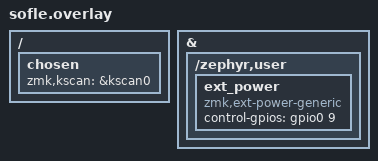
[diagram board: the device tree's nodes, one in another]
/ {
    chosen {
        zmk,kscan = &kscan0;
    };
};

&{/zephyr,user {
    ext_power {
        compatible = "zmk,ext-power-generic";
        control-gpios = <&gpio0 9 GPIO_ACTIVE_HIGH>;
    };
}};
